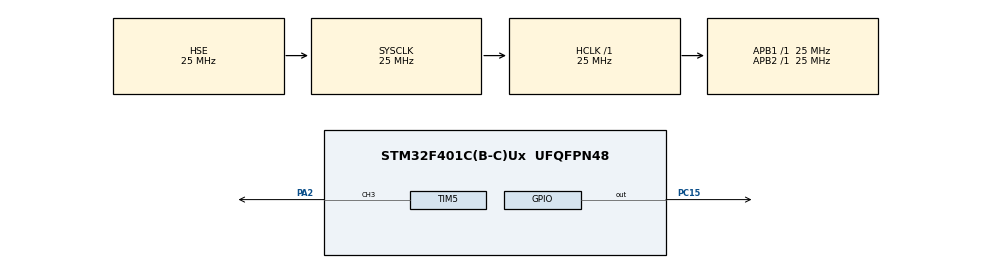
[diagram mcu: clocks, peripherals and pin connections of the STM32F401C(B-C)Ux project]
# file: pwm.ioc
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Dma.Request0=TIM5_CH3/UP
Dma.TIM5_CH3/UP.0.Direction=DMA_MEMORY_TO_PERIPH
Dma.TIM5_CH3/UP.0.FIFOMode=DMA_FIFOMODE_DISABLE
Dma.TIM5_CH3/UP.0.Instance=DMA1_Stream0
Dma.TIM5_CH3/UP.0.MemDataAlignment=DMA_MDATAALIGN_WORD
Dma.TIM5_CH3/UP.0.MemInc=DMA_MINC_ENABLE
Dma.TIM5_CH3/UP.0.Mode=DMA_NORMAL
Dma.TIM5_CH3/UP.0.PeriphDataAlignment=DMA_PDATAALIGN_WORD
Dma.TIM5_CH3/UP.0.PeriphInc=DMA_PINC_DISABLE
Dma.TIM5_CH3/UP.0.Priority=DMA_PRIORITY_LOW
Mcu.Family=STM32F4
Mcu.Name=STM32F401C(B-C)Ux
Mcu.Package=UFQFPN48
NVIC.DMA1_Stream0_IRQn=true\:0\:0\:false\:false\:true\:false\:true\:true
NVIC.PriorityGroup=NVIC_PRIORITYGROUP_4
PA13.Mode=Serial_Wire
PA13.Signal=SYS_JTMS-SWDIO
PA14.Mode=Serial_Wire
PA14.Signal=SYS_JTCK-SWCLK
PA2.Signal=S_TIM5_CH3
PC15-OSC32_OUT.GPIO_PuPd=GPIO_PULLUP
PC15-OSC32_OUT.Signal=GPIO_Output
PH0\ -\ OSC_IN.Mode=HSE-External-Oscillator
PH0\ -\ OSC_IN.Signal=RCC_OSC_IN
PH1\ -\ OSC_OUT.Mode=HSE-External-Oscillator
PH1\ -\ OSC_OUT.Signal=RCC_OSC_OUT
ProjectManager.HeapSize=0x200
ProjectManager.StackSize=0x400
ProjectManager.TargetToolchain=STM32CubeIDE
RCC.48MHZClocksFreq_Value=75000000
RCC.AHBFreq_Value=25000000
RCC.APB1Freq_Value=25000000
RCC.APB1TimFreq_Value=25000000
RCC.APB2Freq_Value=25000000
RCC.APB2TimFreq_Value=25000000
RCC.CortexFreq_Value=25000000
RCC.HCLKFreq_Value=25000000
RCC.HSE_VALUE=25000000
RCC.HSI_VALUE=16000000
RCC.LSE_VALUE=32768
RCC.PLLSourceVirtual=RCC_PLLSOURCE_HSE
RCC.SYSCLKFreq_VALUE=25000000
RCC.SYSCLKSource=RCC_SYSCLKSOURCE_HSE
RCC.VCOOutputFreq_Value=300000000
SH.S_TIM5_CH3.0=TIM5_CH3,PWM Generation3 CH3
TIM5.Channel-PWM\ Generation3\ CH3=TIM_CHANNEL_3
TIM5.Period=100-1
TIM5.Prescaler=25-1
VP_TIM5_VS_ClockSourceINT.Mode=Internal
board=custom

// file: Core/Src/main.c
/* USER CODE BEGIN Header */
/**
  ******************************************************************************
  * @file           : main.c
  * @brief          : Main program body
  ******************************************************************************
  * @attention
  *
  * Copyright (c) 2025 STMicroelectronics.
  * All rights reserved.
  *
  * This software is licensed under terms that can be found in the LICENSE file
  * in the root directory of this software component.
  * If no LICENSE file comes with this software, it is provided AS-IS.
  *
  ******************************************************************************
  */
/* USER CODE END Header */
#include "main.h"

TIM_HandleTypeDef htim5;
DMA_HandleTypeDef hdma_tim5_ch3_up;

void SystemClock_Config(void);
static void MX_GPIO_Init(void);
static void MX_DMA_Init(void);
static void MX_TIM5_Init(void);

int main(void)
{

  /* MCU Configuration--------------------------------------------------------*/

  /* Reset of all peripherals, Initializes the Flash interface and the Systick. */
  HAL_Init();

  /* Configure the system clock */
  SystemClock_Config();

  /* Initialize all configured peripherals */
  MX_GPIO_Init();
  MX_DMA_Init();
  MX_TIM5_Init();
  /* USER CODE BEGIN 2 */
  TIM5->CCR3 = 90;
  HAL_TIM_PWM_Start(&htim5, TIM_CHANNEL_3);

  /* USER CODE END 2 */

  /* Infinite loop */
  /* USER CODE BEGIN WHILE */
  while (1)
  {
	  HAL_Delay(10);
    /* USER CODE END WHILE */

  }
}

void SystemClock_Config(void)
{
  RCC_OscInitTypeDef RCC_OscInitStruct = {0};
  RCC_ClkInitTypeDef RCC_ClkInitStruct = {0};

  /** Configure the main internal regulator output voltage
  */
  __HAL_RCC_PWR_CLK_ENABLE();
  __HAL_PWR_VOLTAGESCALING_CONFIG(PWR_REGULATOR_VOLTAGE_SCALE2);

  /** Initializes the RCC Oscillators according to the specified parameters
  * in the RCC_OscInitTypeDef structure.
  */
  RCC_OscInitStruct.OscillatorType = RCC_OSCILLATORTYPE_HSE;
  RCC_OscInitStruct.HSEState = RCC_HSE_ON;
  RCC_OscInitStruct.PLL.PLLState = RCC_PLL_NONE;
  if (HAL_RCC_OscConfig(&RCC_OscInitStruct) != HAL_OK)
  {
    Error_Handler();
  }

  /** Initializes the CPU, AHB and APB buses clocks
  */
  RCC_ClkInitStruct.ClockType = RCC_CLOCKTYPE_HCLK|RCC_CLOCKTYPE_SYSCLK
                              |RCC_CLOCKTYPE_PCLK1|RCC_CLOCKTYPE_PCLK2;
  RCC_ClkInitStruct.SYSCLKSource = RCC_SYSCLKSOURCE_HSE;
  RCC_ClkInitStruct.AHBCLKDivider = RCC_SYSCLK_DIV1;
  RCC_ClkInitStruct.APB1CLKDivider = RCC_HCLK_DIV1;
  RCC_ClkInitStruct.APB2CLKDivider = RCC_HCLK_DIV1;

  if (HAL_RCC_ClockConfig(&RCC_ClkInitStruct, FLASH_LATENCY_0) != HAL_OK)
  {
    Error_Handler();
  }
}

static void MX_TIM5_Init(void)
{

  TIM_ClockConfigTypeDef sClockSourceConfig = {0};
  TIM_MasterConfigTypeDef sMasterConfig = {0};
  TIM_OC_InitTypeDef sConfigOC = {0};

  htim5.Instance = TIM5;
  htim5.Init.Prescaler = 25-1;
  htim5.Init.CounterMode = TIM_COUNTERMODE_UP;
  htim5.Init.Period = 100-1;
  htim5.Init.ClockDivision = TIM_CLOCKDIVISION_DIV1;
  htim5.Init.AutoReloadPreload = TIM_AUTORELOAD_PRELOAD_DISABLE;
  if (HAL_TIM_Base_Init(&htim5) != HAL_OK)
  {
    Error_Handler();
  }
  sClockSourceConfig.ClockSource = TIM_CLOCKSOURCE_INTERNAL;
  if (HAL_TIM_ConfigClockSource(&htim5, &sClockSourceConfig) != HAL_OK)
  {
    Error_Handler();
  }
  if (HAL_TIM_PWM_Init(&htim5) != HAL_OK)
  {
    Error_Handler();
  }
  sMasterConfig.MasterOutputTrigger = TIM_TRGO_RESET;
  sMasterConfig.MasterSlaveMode = TIM_MASTERSLAVEMODE_DISABLE;
  if (HAL_TIMEx_MasterConfigSynchronization(&htim5, &sMasterConfig) != HAL_OK)
  {
    Error_Handler();
  }
  sConfigOC.OCMode = TIM_OCMODE_PWM1;
  sConfigOC.Pulse = 0;
  sConfigOC.OCPolarity = TIM_OCPOLARITY_HIGH;
  sConfigOC.OCFastMode = TIM_OCFAST_DISABLE;
  if (HAL_TIM_PWM_ConfigChannel(&htim5, &sConfigOC, TIM_CHANNEL_3) != HAL_OK)
  {
    Error_Handler();
  }
  HAL_TIM_MspPostInit(&htim5);

}

static void MX_DMA_Init(void)
{

  /* DMA controller clock enable */
  __HAL_RCC_DMA1_CLK_ENABLE();

  /* DMA interrupt init */
  /* DMA1_Stream0_IRQn interrupt configuration */
  HAL_NVIC_SetPriority(DMA1_Stream0_IRQn, 0, 0);
  HAL_NVIC_EnableIRQ(DMA1_Stream0_IRQn);

}

static void MX_GPIO_Init(void)
{
  GPIO_InitTypeDef GPIO_InitStruct = {0};

  /* GPIO Ports Clock Enable */
  __HAL_RCC_GPIOC_CLK_ENABLE();
  __HAL_RCC_GPIOH_CLK_ENABLE();
  __HAL_RCC_GPIOA_CLK_ENABLE();

  /*Configure GPIO pin Output Level */
  HAL_GPIO_WritePin(GPIOC, GPIO_PIN_15, GPIO_PIN_RESET);

  /*Configure GPIO pin : PC15 */
  GPIO_InitStruct.Pin = GPIO_PIN_15;
  GPIO_InitStruct.Mode = GPIO_MODE_OUTPUT_PP;
  GPIO_InitStruct.Pull = GPIO_PULLUP;
  GPIO_InitStruct.Speed = GPIO_SPEED_FREQ_LOW;
  HAL_GPIO_Init(GPIOC, &GPIO_InitStruct);

}

void Error_Handler(void)
{
  __disable_irq();
  while (1)
  {
  }
}
